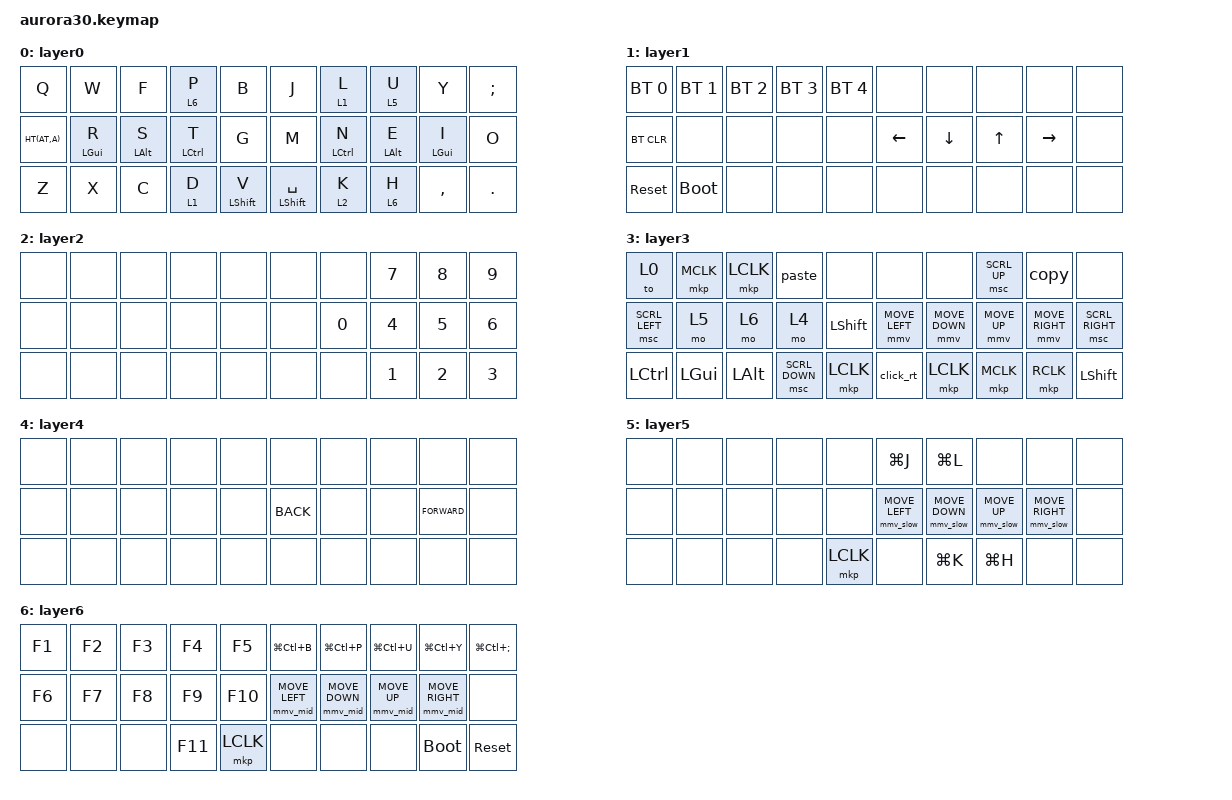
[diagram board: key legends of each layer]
#include <behaviors.dtsi>
#include <dt-bindings/zmk/keys.h>

#define ZMK_POINTING_DEFAULT_MOVE_VAL 3500 
#define ZMK_POINTING_DEFAULT_SCRL_VAL 40   
#include <dt-bindings/zmk/pointing.h>
#include <dt-bindings/zmk/bt.h>


&mmv {
    time-to-max-speed-ms = <250>;
    acceleration-exponent = <2>;
    trigger-period-ms = <8>;
};

&msc {
    time-to-max-speed-ms = <100>;
    acceleration-exponent = <2>;
};

#define HT(hold, tap) &ht hold tap

/* Layers */
#define TIMEOUT_COMBO 20

/ { 
    //      ----------------------    ----------------------
    //      | 00  01  02  03  04 |    | 05  06  07  08  09 |
    //      | 10  11  12  13  14 |    | 15  16  17  18  19 |
    //      | 20  21  22  23  24 |    | 25  26  27  28  29 |
    //      ----------------------    ----------------------

     macros {
        copy: copy {
            compatible = "zmk,behavior-macro";
            #binding-cells = <0>;
            bindings
                = <&macro_press &kp LCTRL>
                , <&macro_tap &kp C>
                , <&macro_release &kp LCTRL>
                ;
        };
        shift_copy: shift_copy {
            compatible = "zmk,behavior-macro";
            #binding-cells = <0>;
            bindings
                = <&macro_press &kp LCTRL &kp LSHFT>
                , <&macro_tap &kp C>
                , <&macro_release &kp LCTRL &kp LSHFT>
                ;
        };
        paste: paste {
            compatible = "zmk,behavior-macro";
            #binding-cells = <0>;
            bindings
                = <&macro_press &kp LCTRL>
                , <&macro_tap &kp V>
                , <&macro_release &kp LCTRL>
                ;
        };
        shift_paste: shift_paste {
            compatible = "zmk,behavior-macro";
            #binding-cells = <0>;
            bindings
                = <&macro_press &kp LCTRL &kp LSHFT>
                , <&macro_tap &kp V>
                , <&macro_release &kp LCTRL &kp LSHFT>
                ;
        };
        click_rt: click_return_layer {
            compatible = "zmk,behavior-macro";
            #binding-cells = <0>;
            bindings
                = <&macro_tap &mkp LCLK &macro_tap &to 0>
                ;
        };
        shifts: combo_both_shifts {
            compatible = "zmk,behavior-macro";
            #binding-cells = <0>;
            bindings
                = <&macro_press &kp LSHFT &kp RSHFT>
                , <&macro_release &kp LSHFT &kp RSHFT>
                ;
        };
    };

    behaviors {
        ht: hold_tap {
            compatible = "zmk,behavior-hold-tap";
            #binding-cells = <2>;
            flavor = "tap-preferred";
            tapping-term-ms = <200>;
            quick-tap-ms = <200>;
            require-prior-idle-ms = <125>;
            bindings = <&kp>, <&kp>;
            display-name = "Hold-tap";
        };
        ms: mod_shift {
            compatible = "zmk,behavior-hold-tap";
            #binding-cells = <2>;
            flavor = "tap-preferred";
            tapping-term-ms = <200>;
            bindings = <&kp>, <&kp>;
            display-name = "Mod-Tap";
        };
        hml: home_row_mod_left {
            compatible = "zmk,behavior-hold-tap";
            #binding-cells = <2>;
            flavor = "balanced";
            require-prior-idle-ms = <150>;
            tapping-term-ms = <280>;
            quick-tap-ms = <175>;
            bindings = <&kp>, <&kp>;
            hold-trigger-key-positions = <5  6  7  8  9 15  16  17  18  19 25  26  27  28  29>; // List of keys on the right side of the keyboard
            hold-trigger-on-release;
        };
        hmr: home_row_mod_right {
            compatible = "zmk,behavior-hold-tap";
            #binding-cells = <2>;
            flavor = "balanced";
            require-prior-idle-ms = <150>;
            tapping-term-ms = <280>;
            quick-tap-ms = <175>;
            bindings = <&kp>, <&kp>;
            hold-trigger-key-positions = <0  1  2  3  4 10  11  12  13  14 20  21  22  23  24>; // List of keys on the left side of the keyboard
            hold-trigger-on-release;
        };
        mmv_slow: mmv_slow {
            compatible = "zmk,behavior-input-two-axis";
            #binding-cells = <1>;
            x-input-code = <INPUT_REL_X>;
            y-input-code = <INPUT_REL_Y>;
            time-to-max-speed-ms = <2000>;
            acceleration-exponent = <1>;
            trigger-period-ms = <8>;
        };
        mmv_mid: mmv_mid {
            compatible = "zmk,behavior-input-two-axis";
            #binding-cells = <1>;
            x-input-code = <INPUT_REL_X>;
            y-input-code = <INPUT_REL_Y>;
            time-to-max-speed-ms = <1000>;
            acceleration-exponent = <1>;
            trigger-period-ms = <8>;
        };
    };

    mmv_slow_listener: mmv_slow_listener {
        compatible = "zmk,input-listener";
        device = <&mmv_slow>;
    };
    mmv_mid_listener: mmv_mid_listener {
        compatible = "zmk,input-listener";
        device = <&mmv_mid>;
    };

    combos {
        compatible = "zmk,combos";
        combo_bspc {
            timeout-ms = <TIMEOUT_COMBO>;
            key-positions = <6 7>;
            bindings = <&kp BSPC>;
            layers = <0>;
        };
        combo_enter {
            timeout-ms = <TIMEOUT_COMBO>;
            key-positions = <17 18>;
            bindings = <&kp ENTER>;
            layers = <0>;
        };
        combo_tab {
            timeout-ms = <TIMEOUT_COMBO>;
            key-positions = <11 12>;
            bindings = <&kp TAB>;
            layers = <0>;
        };
        combo_shifts {
            timeout-ms = <TIMEOUT_COMBO>;
            key-positions = <25 26>;
            bindings = <&shifts>;
            layers = <0>;
        };
        combo_esc {
            timeout-ms = <TIMEOUT_COMBO>;
            key-positions = <16 17>;
            bindings = <&kp ESC>;
            layers = <0>;
        };
        combo_to3 {
            timeout-ms = <TIMEOUT_COMBO>;
            key-positions = <12 13>;
            bindings = <&to 3>;
            layers = <0>;
        };
        combo_lbkt {
            timeout-ms = <TIMEOUT_COMBO>;
            key-positions = <1 11>;
            bindings = <&kp LBKT>;
            layers = <0>;
        };
        combo_lbrc {
            timeout-ms = <TIMEOUT_COMBO>;
            key-positions = <2 12>;
            bindings = <&kp LBRC>;
            layers = <0>;
        };
        combo_rbrc {
            timeout-ms = <TIMEOUT_COMBO>;
            key-positions = <7 17>;
            bindings = <&kp RBRC>;
            layers = <0>;
        };
        combo_amps {
            timeout-ms = <TIMEOUT_COMBO>;
            key-positions = <5 6>;
            bindings = <&kp AMPS>;
            layers = <0>;
        };
        combo_apos {
            timeout-ms = <TIMEOUT_COMBO>;
            key-positions = <4 14>;
            bindings = <&kp APOS>;
            layers = <0>;
        };
        combo_rpar {
            timeout-ms = <TIMEOUT_COMBO>;
            key-positions = <6 16>;
            bindings = <&kp RPAR>;
            layers = <0>;
        };
        combo_lpar {
            timeout-ms = <TIMEOUT_COMBO>;
            key-positions = <3 13>;
            bindings = <&kp LPAR>;
            layers = <0>;
        };
        combo_pipe {
            timeout-ms = <TIMEOUT_COMBO>;
            key-positions = <3 4>;
            bindings = <&kp PIPE>;
            layers = <0>;
        };
        combo_plus {
            timeout-ms = <TIMEOUT_COMBO>;
            key-positions = <15 25>;
            bindings = <&kp PLUS>;
            layers = <0>;
        };
        combo_grave {
            timeout-ms = <TIMEOUT_COMBO>;
            key-positions = <21 22>;
            bindings = <&kp GRAVE>;
            layers = <0>;
        };
        combo_rbkt {
            timeout-ms = <TIMEOUT_COMBO>;
            key-positions = <8 18>;
            bindings = <&kp RBKT>;
            layers = <0>;
        };
        combo_equal {
            timeout-ms = <TIMEOUT_COMBO>;
            key-positions = <22 23>;
            bindings = <&kp EQUAL>;
            layers = <0>;
        };
        combo_dollar {
            timeout-ms = <TIMEOUT_COMBO>;
            key-positions = <23 24>;
            bindings = <&kp DLLR>;
            layers = <0>;
        };
        combo_hash {
            timeout-ms = <TIMEOUT_COMBO>;
            key-positions = <12 22>;
            bindings = <&kp HASH>;
            layers = <0>;
        };
        combo_double_quote {
            timeout-ms = <TIMEOUT_COMBO>;
            key-positions = <5 15>;
            bindings = <&kp DQT>;
            layers = <0>;
        };
        combo_underscore {
            timeout-ms = <TIMEOUT_COMBO>;
            key-positions = <27 28>;
            bindings = <&kp UNDERSCORE>;
            layers = <0>;
        };
        combo_qmark {
            timeout-ms = <TIMEOUT_COMBO>;
            key-positions = <15 16>;
            bindings = <&kp QMARK>;
            layers = <0>;
        };
        combo_excl {
            timeout-ms = <TIMEOUT_COMBO>;
            key-positions = <1 2>;
            bindings = <&kp EXCL>;
            layers = <0>;
        };
        combo_pct {
            timeout-ms = <TIMEOUT_COMBO>;
            key-positions = <6 8>;
            bindings = <&kp PRCNT>;
            layers = <0>;
        };
        combo_tilde {
            timeout-ms = <TIMEOUT_COMBO>;
            key-positions = <7 8>;
            bindings = <&kp TILDE>;
            layers = <0>;
        };
        combo_fslh {
            timeout-ms = <TIMEOUT_COMBO>;
            key-positions = <2 3>;
            bindings = <&kp FSLH>;
            layers = <0>;
        };
        combo_caret {
            timeout-ms = <TIMEOUT_COMBO>;
            key-positions = <11 13>;
            bindings = <&kp CARET>;
            layers = <0>;
        };
        combo_asterisk {
            timeout-ms = <TIMEOUT_COMBO>;
            key-positions = <1 3>;
            bindings = <&kp STAR>;
            layers = <0>;
        };
        combo_backslash {
            timeout-ms = <TIMEOUT_COMBO>;
            key-positions = <13 14>;
            bindings = <&kp BSLH>;
            layers = <0>;
        };
        combo_dash {
            timeout-ms = <TIMEOUT_COMBO>;
            key-positions = <26 27>;
            bindings = <&kp MINUS>;
            layers = <0>;
        };
    };

    keymap {
        compatible = "zmk,keymap";

        layer0 {
            bindings = <
                // 0        1             2           3             4                   5                 6             7             8             9
                &kp Q       &kp W         &kp F       &lt 6 P       &kp B               &kp J             &lt 1 L       &lt 5 U       &kp Y         &kp SEMI
                // 10       11            12          13            14                  15                16            17            18            19
                HT(AT,A)    &hml LGUI R   &hml LALT S &hml LCTRL T  &kp G               &kp M             &hmr LCTRL N  &hmr LALT E   &hmr LGUI I   &kp O
                // 20       21            22          23            24                  25                26            27            28            29
                &kp Z       &kp X         &kp C       &lt 1 D       &ms LSHFT V         &ms LSHFT SPACE   &lt 2 K       &lt 6 H       &kp COMMA     &kp DOT
            >;
        };

        layer1 {
            bindings = <
              &bt BT_SEL 0  &bt BT_SEL 1  &bt BT_SEL 2  &bt BT_SEL 3  &bt BT_SEL 4        &none    &none     &none   &none     &none
              &bt BT_CLR    &none         &none         &none         &none               &kp LEFT &kp DOWN  &kp UP  &kp RIGHT &none
              &sys_reset    &bootloader   &none         &none         &none               &none    &none     &none   &none     &none
            >;
        };

        layer2 {
            bindings = <
              &none &none &none &none &none    &none    &none     &kp N7  &kp N8  &kp N9
              &none &none &none &none &none    &none    &kp N0    &kp N4  &kp N5  &kp N6
              &none &none &none &none &none    &none    &none     &kp N1  &kp N2  &kp N3
            >;
        };

        layer3 {
            bindings = <
              &to 0           &mkp MCLK   &mkp LCLK   &paste            &none             &none             &none               &msc SCRL_UP    &copy             &none
              &msc SCRL_LEFT  &mo 5       &mo 6       &mo 4             &kp LSHFT         &mmv MOVE_LEFT    &mmv MOVE_DOWN      &mmv MOVE_UP    &mmv MOVE_RIGHT   &msc SCRL_RIGHT
              &kp LCTRL       &kp LGUI    &kp LALT    &msc SCRL_DOWN    &mkp LCLK         &click_rt         &mkp LCLK           &mkp MCLK       &mkp RCLK         &kp LSHFT
            >;
        };

        layer4 {
            bindings = <
              &none &none &none &none &none    &none        &none   &none   &none         &none
              &none &none &none &none &none    &kp K_BACK   &none   &none   &kp K_FORWARD &none
              &none &none &none &none &none    &none        &none   &none   &none         &none
            >;
        };

        layer5 {
            bindings = <
              &none &none &none &none &none         &kp LG(J)              &kp LG(L)                 &none                 &none                 &none
              &none &none &none &none &none         &mmv_slow MOVE_LEFT    &mmv_slow MOVE_DOWN       &mmv_slow MOVE_UP     &mmv_slow MOVE_RIGHT  &none
              &none &none &none &none &mkp LCLK     &none                  &kp LG(K)                 &kp LG(H)             &none                 &none
            >;
        };

        layer6 {
            bindings = <
              &kp F1  &kp F2  &kp F3  &kp F4  &kp F5      &kp LG(LC(B))         &kp LG(LC(P))         &kp LG(LC(U))     &kp LG(LC(Y))         &kp LG(LC(SEMI))
              &kp F6  &kp F7  &kp F8  &kp F9  &kp F10     &mmv_mid MOVE_LEFT    &mmv_mid MOVE_DOWN    &mmv_mid MOVE_UP  &mmv_mid MOVE_RIGHT   &none
              &none   &none   &none   &kp F11 &mkp LCLK   &none                 &none                 &none             &bootloader           &sys_reset
            >;
        };
    };
};
